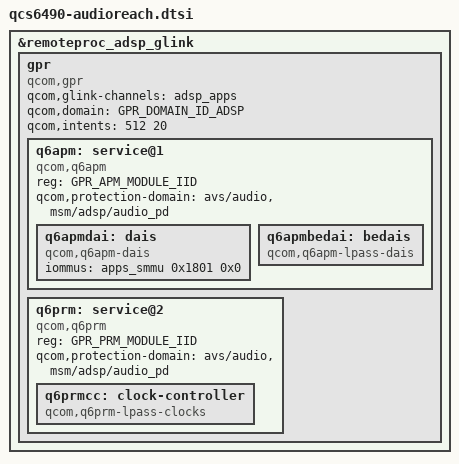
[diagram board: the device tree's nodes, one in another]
// SPDX-License-Identifier: BSD-3-Clause
/*
 * Copyright (c) Qualcomm Technologies, Inc. and/or its subsidiaries.
 *
 * Common definitions for SC7280-based boards with AudioReach.
 */

#include <dt-bindings/clock/qcom,lpass-sc7280.h>
#include <dt-bindings/soc/qcom,gpr.h>
#include <dt-bindings/sound/qcom,q6afe.h>
#include <dt-bindings/sound/qcom,q6dsp-lpass-ports.h>

&remoteproc_adsp_glink {
	/delete-node/ apr;

	gpr {
		compatible = "qcom,gpr";
		qcom,glink-channels = "adsp_apps";
		qcom,domain = <GPR_DOMAIN_ID_ADSP>;
		qcom,intents = <512 20>;
		#address-cells = <1>;
		#size-cells = <0>;

		q6apm: service@1 {
			compatible = "qcom,q6apm";
			reg = <GPR_APM_MODULE_IID>;
			#sound-dai-cells = <0>;
			qcom,protection-domain = "avs/audio", "msm/adsp/audio_pd";

			q6apmdai: dais {
				compatible = "qcom,q6apm-dais";
				iommus = <&apps_smmu 0x1801 0x0>;
			};

			q6apmbedai: bedais {
				compatible = "qcom,q6apm-lpass-dais";
				#sound-dai-cells = <1>;
			};
		};

		q6prm: service@2 {
			compatible = "qcom,q6prm";
			reg = <GPR_PRM_MODULE_IID>;
			qcom,protection-domain = "avs/audio", "msm/adsp/audio_pd";

			q6prmcc: clock-controller {
				compatible = "qcom,q6prm-lpass-clocks";
				#clock-cells = <2>;
			};
		};
	};
};
